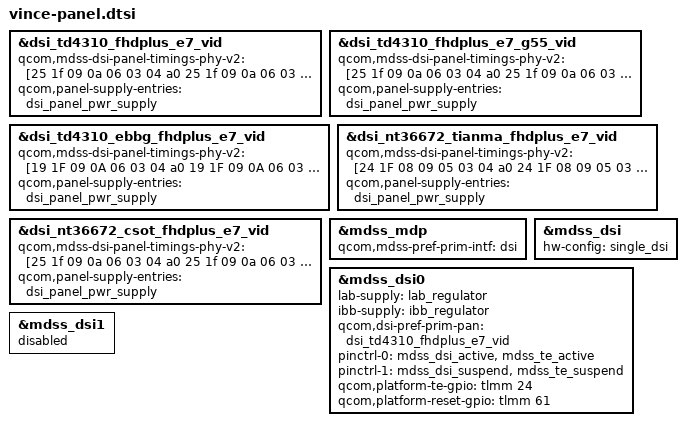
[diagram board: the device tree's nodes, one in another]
/* Copyright (c) 2015-2016, The Linux Foundation. All rights reserved.
 * Copyright (C) 2018 XiaoMi, Inc.
 *
 * This program is free software; you can redistribute it and/or modify
 * it under the terms of the GNU General Public License version 2 and
 * only version 2 as published by the Free Software Foundation.
 *
 * This program is distributed in the hope that it will be useful,
 * but WITHOUT ANY WARRANTY; without even the implied warranty of
 * MERCHANTABILITY or FITNESS FOR A PARTICULAR PURPOSE.  See the
 * GNU General Public License for more details.
 */

#include "dsi-panel-td4310-fhdplus-video_e7.dtsi"
#include "dsi-panel-td4310-fhdplus-video_e7_g55.dtsi"
#include "dsi-panel-td4310-ebbg-fhdplus-video_e7.dtsi"
#include "dsi-panel-nt36672-tianma-fhdplus-video_e7.dtsi"
#include "dsi-panel-nt36672-csot-fhdplus-video_e7.dtsi"

&dsi_td4310_fhdplus_e7_vid {
	qcom,mdss-dsi-panel-timings-phy-v2 = [25 1f 09 0a 06 03 04 a0
	      25 1f 09 0a 06 03 04 a0
	      25 1f 09 0a 06 03 04 a0
	      25 1f 09 0a 06 03 04 a0
	      25 1f 08 0a 06 03 04 a0];
};

&dsi_td4310_fhdplus_e7_g55_vid {
	qcom,mdss-dsi-panel-timings-phy-v2 = [25 1f 09 0a 06 03 04 a0
	      25 1f 09 0a 06 03 04 a0
	      25 1f 09 0a 06 03 04 a0
	      25 1f 09 0a 06 03 04 a0
	      25 1f 08 0a 06 03 04 a0];
};

&dsi_td4310_ebbg_fhdplus_e7_vid {
	qcom,mdss-dsi-panel-timings-phy-v2 = [19 1F 09 0A 06 03 04 a0
		19 1F 09 0A 06 03 04 a0
		19 1F 09 0A 06 03 04 a0
		19 1F 09 0A 06 03 04 a0
		19 1E 08 0A 06 03 04 a0];
};

&dsi_nt36672_tianma_fhdplus_e7_vid {
	qcom,mdss-dsi-panel-timings-phy-v2 = [24 1F 08 09 05 03 04 a0
		24 1F 08 09 05 03 04 a0
		24 1F 08 09 05 03 04 a0
		24 1F 08 09 05 03 04 a0
		24 1C 08 09 05 03 04 a0];
};

&dsi_nt36672_csot_fhdplus_e7_vid {
	qcom,mdss-dsi-panel-timings-phy-v2 = [25 1f 09 0a 06 03 04 a0
		25 1f 09 0a 06 03 04 a0
		25 1f 09 0a 06 03 04 a0
		25 1f 09 0a 06 03 04 a0
		25 1e 08 0a 06 03 04 a0];
};

&mdss_mdp {
	qcom,mdss-pref-prim-intf = "dsi";
};

&mdss_dsi {
	hw-config = "single_dsi";
};

&mdss_dsi0 {
	lab-supply = <&lab_regulator>;
	ibb-supply = <&ibb_regulator>;
	/delete-property/ vdd-supply;

	qcom,dsi-pref-prim-pan = <&dsi_td4310_fhdplus_e7_vid>;
	pinctrl-names = "mdss_default", "mdss_sleep";
	pinctrl-0 = <&mdss_dsi_active &mdss_te_active>;
	pinctrl-1 = <&mdss_dsi_suspend &mdss_te_suspend>;
	qcom,platform-te-gpio = <&tlmm 24 0>;
	qcom,platform-reset-gpio = <&tlmm 61 0>;
};

&mdss_dsi1 {
	status = "disabled";
};

/*add begin for E7 display*/
&dsi_td4310_fhdplus_e7_vid {
	qcom,panel-supply-entries = <&dsi_panel_pwr_supply>;
};

&dsi_td4310_fhdplus_e7_g55_vid {
	qcom,panel-supply-entries = <&dsi_panel_pwr_supply>;
};


&dsi_td4310_ebbg_fhdplus_e7_vid {
	qcom,panel-supply-entries = <&dsi_panel_pwr_supply>;
};

&dsi_nt36672_tianma_fhdplus_e7_vid {
	qcom,panel-supply-entries = <&dsi_panel_pwr_supply>;
};

&dsi_nt36672_csot_fhdplus_e7_vid {
	qcom,panel-supply-entries = <&dsi_panel_pwr_supply>;
};
/*add end for E7 display*/
	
